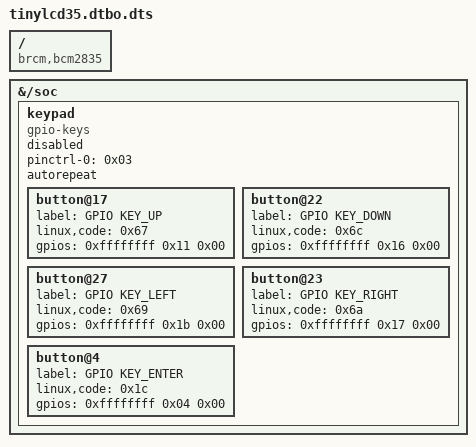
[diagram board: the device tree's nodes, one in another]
/dts-v1/;

/ {
	compatible = "brcm,bcm2835";

	fragment@0 {
		target = <0xffffffff>;

		__overlay__ {
			status = "okay";
		};
	};

	fragment@1 {
		target = <0xffffffff>;

		__overlay__ {
			status = "disabled";
		};
	};

	fragment@2 {
		target = <0xffffffff>;

		__overlay__ {
			status = "disabled";
		};
	};

	fragment@3 {
		target = <0xffffffff>;

		__overlay__ {

			tinylcd35_pins {
				brcm,pins = <0x19 0x18 0x12>;
				brcm,function = <0x01>;
				phandle = <0x01>;
			};

			tinylcd35_ts_pins {
				brcm,pins = <0x05>;
				brcm,function = <0x00>;
				phandle = <0x02>;
			};

			keypad_pins {
				brcm,pins = <0x04 0x11 0x16 0x17 0x1b>;
				brcm,function = <0x00>;
				brcm,pull = <0x01>;
				phandle = <0x03>;
			};
		};
	};

	fragment@4 {
		target = <0xffffffff>;

		__overlay__ {
			#address-cells = <0x01>;
			#size-cells = <0x00>;

			tinylcd35@0 {
				compatible = "neosec,tinylcd";
				reg = <0x00>;
				pinctrl-names = "default";
				pinctrl-0 = <0x01 0x02>;
				spi-max-frequency = <0x2dc6c00>;
				rotate = <0x10e>;
				fps = <0x14>;
				bgr;
				buswidth = <0x08>;
				reset-gpios = <0xffffffff 0x19 0x01>;
				dc-gpios = <0xffffffff 0x18 0x00>;
				led-gpios = <0xffffffff 0x12 0x00>;
				debug = <0x00>;
				init = <0x10000b0 0x80 0x10000c0 0x0a 0x0a 0x10000c1 0x01 0x01 0x10000c2 0x33 0x10000c5 0x00 0x42 0x80 0x10000b1 0xd0 0x11 0x10000b4 0x02 0x10000b6 0x00 0x22 0x3b 0x10000b7 0x07 0x1000036 0x58 0x10000f0 0x36 0xa5 0xd3 0x10000e5 0x80 0x10000e5 0x01 0x10000b3 0x00 0x10000e5 0x00 0x10000f0 0x36 0xa5 0x53 0x10000e0 0x00 0x35 0x33 0x00 0x00 0x00 0x00 0x35 0x33 0x00 0x00 0x00 0x100003a 0x55 0x1000011 0x2000001 0x1000029>;
				phandle = <0x04>;
			};

			tinylcd35_ts@1 {
				compatible = "ti,ads7846";
				reg = <0x01>;
				status = "disabled";
				spi-max-frequency = <0x1e8480>;
				interrupts = <0x05 0x02>;
				interrupt-parent = <0xffffffff>;
				pendown-gpio = <0xffffffff 0x05 0x00>;
				ti,x-plate-ohms = [00 64];
				ti,pressure-max = [00 ff];
				phandle = <0x05>;
			};
		};
	};

	fragment@5 {
		target = <0xffffffff>;

		__dormant__ {
			#address-cells = <0x01>;
			#size-cells = <0x00>;
			status = "okay";

			pcf8563@51 {
				compatible = "nxp,pcf8563";
				reg = <0x51>;
				status = "okay";
				phandle = <0x07>;
			};
		};
	};

	fragment@6 {
		target = <0xffffffff>;

		__dormant__ {
			#address-cells = <0x01>;
			#size-cells = <0x00>;
			status = "okay";

			ds1307@68 {
				compatible = "dallas,ds1307";
				reg = <0x68>;
				status = "okay";
				phandle = <0x08>;
			};
		};
	};

	fragment@7 {
		target-path = "/soc";

		__overlay__ {

			keypad {
				compatible = "gpio-keys";
				pinctrl-names = "default";
				pinctrl-0 = <0x03>;
				status = "disabled";
				autorepeat;
				phandle = <0x06>;

				button@17 {
					label = "GPIO KEY_UP";
					linux,code = <0x67>;
					gpios = <0xffffffff 0x11 0x00>;
				};

				button@22 {
					label = "GPIO KEY_DOWN";
					linux,code = <0x6c>;
					gpios = <0xffffffff 0x16 0x00>;
				};

				button@27 {
					label = "GPIO KEY_LEFT";
					linux,code = <0x69>;
					gpios = <0xffffffff 0x1b 0x00>;
				};

				button@23 {
					label = "GPIO KEY_RIGHT";
					linux,code = <0x6a>;
					gpios = <0xffffffff 0x17 0x00>;
				};

				button@4 {
					label = "GPIO KEY_ENTER";
					linux,code = <0x1c>;
					gpios = <0xffffffff 0x04 0x00>;
				};
			};
		};
	};

	__overrides__ {
		speed = <0x04 0x7370692d 0x6d61782d 0x66726571 0x75656e63 0x793a3000>;
		rotate = [00 00 00 04 72 6f 74 61 74 65 3a 30 00];
		fps = [00 00 00 04 66 70 73 3a 30 00];
		debug = <0x04 0x64656275 0x673a3000>;
		touch = [00 00 00 05 73 74 61 74 75 73 00];
		touchgpio = <0x02 0x6272636d 0x2c70696e 0x733a3000 0x05 0x696e7465 0x72727570 0x74733a30 0x00 0x570656e 0x646f776e 0x2d677069 0x6f3a3400>;
		xohms = [00 00 00 05 74 69 2c 78 2d 70 6c 61 74 65 2d 6f 68 6d 73 3b 30 00];
		rtc-pcf = [00 00 00 00 3d 35 00];
		rtc-ds = [00 00 00 00 3d 36 00];
		keypad = [00 00 00 06 73 74 61 74 75 73 00];
	};

	__symbols__ {
		tinylcd35_pins = "/fragment@3/__overlay__/tinylcd35_pins";
		tinylcd35_ts_pins = "/fragment@3/__overlay__/tinylcd35_ts_pins";
		keypad_pins = "/fragment@3/__overlay__/keypad_pins";
		tinylcd35 = "/fragment@4/__overlay__/tinylcd35@0";
		tinylcd35_ts = "/fragment@4/__overlay__/tinylcd35_ts@1";
		pcf8563 = "/fragment@5/__dormant__/pcf8563@51";
		ds1307 = "/fragment@6/__dormant__/ds1307@68";
		keypad = "/fragment@7/__overlay__/keypad";
	};

	__fixups__ {
		spi0 = "/fragment@0:target:0\0/fragment@4:target:0";
		spidev0 = "/fragment@1:target:0";
		spidev1 = "/fragment@2:target:0";
		gpio = "/fragment@3:target:0\0/fragment@4/__overlay__/tinylcd35@0:reset-gpios:0\0/fragment@4/__overlay__/tinylcd35@0:dc-gpios:0\0/fragment@4/__overlay__/tinylcd35@0:led-gpios:0\0/fragment@4/__overlay__/tinylcd35_ts@1:interrupt-parent:0\0/fragment@4/__overlay__/tinylcd35_ts@1:pendown-gpio:0\0/fragment@7/__overlay__/keypad/button@17:gpios:0\0/fragment@7/__overlay__/keypad/button@22:gpios:0\0/fragment@7/__overlay__/keypad/button@27:gpios:0\0/fragment@7/__overlay__/keypad/button@23:gpios:0\0/fragment@7/__overlay__/keypad/button@4:gpios:0";
		i2c1 = "/fragment@5:target:0\0/fragment@6:target:0";
	};

	__local_fixups__ {

		fragment@4 {

			__overlay__ {

				tinylcd35@0 {
					pinctrl-0 = <0x00 0x04>;
				};
			};
		};

		fragment@7 {

			__overlay__ {

				keypad {
					pinctrl-0 = <0x00>;
				};
			};
		};

		__overrides__ {
			speed = <0x00>;
			rotate = <0x00>;
			fps = <0x00>;
			debug = <0x00>;
			touch = <0x00>;
			touchgpio = <0x00 0x10 0x21>;
			xohms = <0x00>;
			keypad = <0x00>;
		};
	};
};
